# WS63 register map
File version: 1.0
CPU: other r0p0, little endian, MPU, FPU, 3 interrupt priority bits
Registers are 32-bit, read-write, reset 0x0 unless marked. A register's access mark holds for its fields unless they carry their own. Offsets are from the block's base; [hi:lo] are bit positions; {n}, {i} and the like mark numbered series.

## SPI0 — SPI0 master/slave controller (SSI v151)
Base 0x44020000
Same registers: SPI1 0x44021000
0x00 SPI_ER — SPI enable register
  [0] spi_en — SPI enable: 0=disabled; 1=enabled
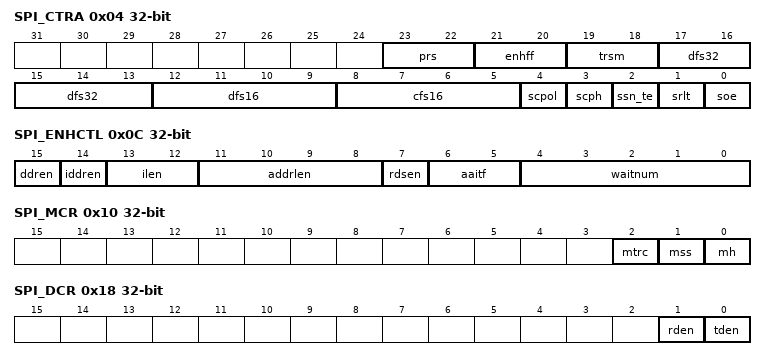
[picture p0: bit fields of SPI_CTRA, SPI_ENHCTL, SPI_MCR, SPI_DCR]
0x04 SPI_CTRA — SPI control register 0
  [23:22] prs — Serial protocol selection
  [21:20] enhff — Enhanced SPI frame format
  [19:18] trsm — Transfer mode: 00=TX/RX; 01=TX only; 10=RX only
    0=TxRx (Transmit and Receive); 1=TxOnly (Transmit Only); 2=RxOnly (Receive Only)
  [17:13] dfs32 — Data frame size in 32-bit mode (0=4bit; up to 31=35bit)
  [12:9] dfs16 — Data frame size in 16-bit transfer mode
  [8:5] cfs16 — Control frame size in 16-bit transfer mode
  [4] scpol — Clock polarity: 0=low idle; 1=high idle
    0=LowIdle (SCK idle low); 1=HighIdle (SCK idle high)
  [3] scph — Clock phase: 0=first edge sample; 1=second edge sample
    0=FirstEdge (Sample on first clock edge); 1=SecondEdge (Sample on second clock edge)
  [2] ssn_te — Slave-select toggle enable
  [1] srlt — Shift register loop test control
  [0] soe — Shift register loop test: 0=normal; 1=loopback
0x08 SPI_CTRB — SPI control register 1 (master only)
  [15:0] ndf — Number of data frames (master TX only mode)
0x0C SPI_ENHCTL — Enhanced control register (Dual/Quad/Octal)
  [15] ddren — Data DDR enable
  [14] iddren — Instruction DDR enable
  [13:12] ilen — Instruction phase length selector
  [11:8] addrlen — Address phase length selector
  [7] rdsen — Read data strobe enable
  [6:5] aaitf — Address and instruction transfer format
  [4:0] waitnum — Wait cycles between control and data phases
0x10 SPI_MCR — Microwire control register
  [2] mtrc — Microwire transfer direction
  [1] mss — Microwire sequential transfer mode
  [0] mh — Microwire handshaking enable
0x14 SPI_BRS — Baud rate select register
  [15:0] frdv — Even clock divider (master): SCK = SSI_CLK / FRDV
0x18 SPI_DCR — DMA control register
  [1] rden — RX DMA enable
  [0] tden — TX DMA enable
0x1C SPI_DRDL — DMA RX data level
  [7:0] dma_rx_data_level — DMA RX FIFO threshold
0x20 SPI_DTDL — DMA TX data level
  [7:0] dma_tx_data_level — DMA TX FIFO threshold
0x24 SPI_RSDR — RX sample delay register
  [7:0] rxdsd — RX sample delay in SSI clock cycles
0x28 SPI_TDER — Transmit drive edge register
  [7:0] txdde — Transmit data drive edge delay
{0x2C+4i} SPI_DRNM{i} (i=0..35) — Data register window (FIFO read/write)
  [31:0] datar — Write pushes TX FIFO; read pops RX FIFO
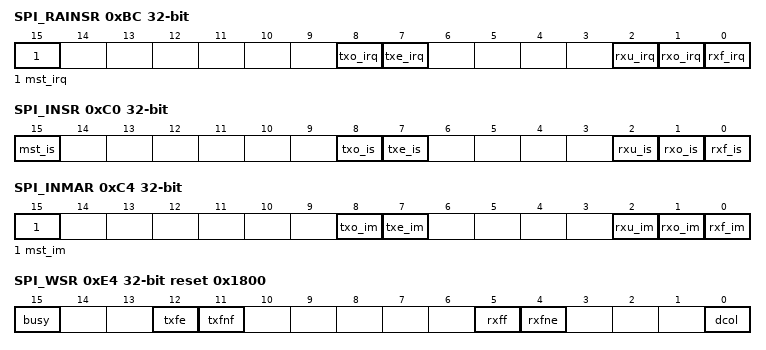
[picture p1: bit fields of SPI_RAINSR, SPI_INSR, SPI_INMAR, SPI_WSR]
0xBC SPI_RAINSR ro — Raw interrupt status register
  [15] mst_irq — Multi-master contention raw status
  [8] txo_irq — TX FIFO overflow raw status
  [7] txe_irq — TX FIFO empty raw status
  [2] rxu_irq — RX FIFO underflow raw status
  [1] rxo_irq — RX FIFO overflow raw status
  [0] rxf_irq — RX FIFO full raw status
0xC0 SPI_INSR ro — Interrupt status register (masked)
  [15] mst_is — Multi-master interrupt status
  [8] txo_is — TX overflow interrupt status
  [7] txe_is — TX empty interrupt status
  [2] rxu_is — RX underflow interrupt status
  [1] rxo_is — RX overflow interrupt status
  [0] rxf_is — RX full interrupt status
0xC4 SPI_INMAR — Interrupt mask register
  [15] mst_im — Multi-master interrupt mask
  [8] txo_im — TX overflow interrupt mask
  [7] txe_im — TX empty interrupt mask
  [2] rxu_im — RX underflow interrupt mask
  [1] rxo_im — RX overflow interrupt mask
  [0] rxf_im — RX full interrupt mask
0xC8 SPI_SLENR — Slave enable register (master only)
  [15:0] slave_enable — One enable bit per slave-select output
0xCC SPI_TWLR — TX FIFO threshold level
  [7:0] tx_fifo_threshold
0xD0 SPI_TLR ro — TX FIFO level register
  [7:0] tx_fifo_level — TX FIFO data level
0xD4 SPI_TFOFICR ro — TX FIFO overflow interrupt clear-on-read register
  [0] cis — Reading clears the TX FIFO overflow interrupt
0xD8 SPI_RWLR — RX FIFO threshold level
  [7:0] rx_fifo_threshold
0xDC SPI_RLR ro — RX FIFO level register
  [7:0] rx_fifo_level — RX FIFO data level
0xE0 SPI_RFFICR ro — RX FIFO underflow interrupt clear-on-read register
  [0] cis — Reading clears the RX FIFO underflow interrupt
0xE4 SPI_WSR ro reset 0x1800 — Status register. Bit layout matches the HiSilicon SSI v151 silicon (vendor hal_spi_v151_regs_def.h spi_wsr_data), NOT the textbook DesignWare SR: the FIFO/busy flags are spread out, not packed in bits 0..6. Verified on WS63 silicon 2026-06-14 (idle reads 0x1800 = TXFNF | TXFE).
  [15] busy — SPI busy flag (serial transfer in progress)
  [12] txfe — TX FIFO empty
  [11] txfnf — TX FIFO not full
  [5] rxff — RX FIFO full
  [4] rxfne — RX FIFO not empty
  [0] dcol — Data collision error (master): the last transfer was halted because another master asserted ss_in_n. Cleared on read.
0xE8 SPI_MSTICR ro — Multi-master interrupt clear-on-read register
  [0] cis — Reading clears the multi-master interrupt
0xEC SPI_ID ro — SSI component version identifier
  [31:0] id — ASCII-encoded component version
0xF0 SPI_RSVD — Vendor extension control register
  [31:0] value — Vendor extension control value
0xF4 SPI_RXOICR ro — RX FIFO overflow interrupt clear-on-read register
  [0] cis — Reading clears the RX FIFO overflow interrupt
0xF8 SPI_ICR ro — Combined interrupt clear-on-read register
  [0] cis — Reading clears TX overflow, RX underflow/overflow, and multi-master interrupts
